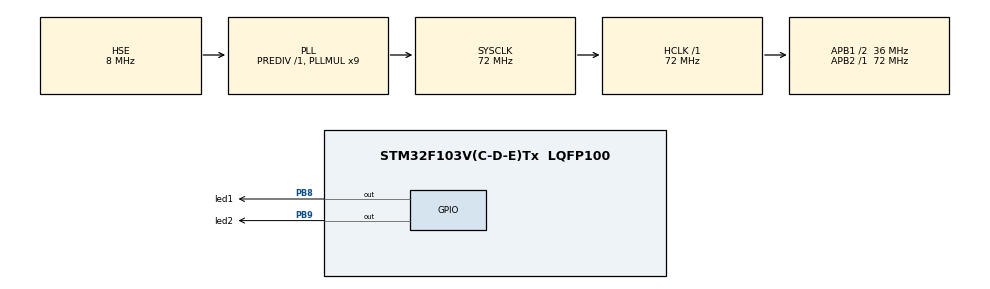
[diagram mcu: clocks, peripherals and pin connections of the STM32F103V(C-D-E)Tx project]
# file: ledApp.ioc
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Mcu.Family=STM32F1
RCC.PLLSourceVirtual=RCC_PLLSOURCE_HSE
PC15-OSC32_OUT.Mode=LSE-External-Oscillator
PB9.GPIO_Label=led2
RCC.APB1CLKDivider=RCC_HCLK_DIV2
PC14-OSC32_IN.Signal=RCC_OSC32_IN
RCC.SYSCLKSource=RCC_SYSCLKSOURCE_PLLCLK
ProjectManager.StackSize=0x400
PA13.Signal=SYS_JTMS-SWDIO
PB8.GPIO_Label=led1
ProjectManager.TargetToolchain=MDK-ARM V5
RCC.HCLKFreq_Value=72000000
RCC.APB2TimFreq_Value=72000000
OSC_IN.Signal=RCC_OSC_IN
RCC.USBFreq_Value=72000000
OSC_OUT.Mode=HSE-External-Oscillator
OSC_OUT.Signal=RCC_OSC_OUT
PC15-OSC32_OUT.Signal=RCC_OSC32_OUT
RCC.AHBFreq_Value=72000000
PB3.Mode=JTAG_5_pins
board=custom
PA15.Mode=JTAG_5_pins
RCC.PLLMUL=RCC_PLL_MUL9
RCC.APB2Freq_Value=72000000
PB4.Mode=JTAG_5_pins
PC14-OSC32_IN.Mode=LSE-External-Oscillator
PA14.Mode=JTAG_5_pins
PA13.Mode=JTAG_5_pins
Mcu.Name=STM32F103V(C-D-E)Tx
PB3.Signal=SYS_JTDO-TRACESWO
RCC.SYSCLKFreq_VALUE=72000000
Mcu.Package=LQFP100
PB9.Signal=GPIO_Output
OSC_IN.Mode=HSE-External-Oscillator
PA14.Signal=SYS_JTCK-SWCLK
PA15.Signal=SYS_JTDI
ProjectManager.HeapSize=0x200
NVIC.PriorityGroup=NVIC_PRIORITYGROUP_4
RCC.APB1TimFreq_Value=72000000
PB8.Signal=GPIO_Output
RCC.APB1Freq_Value=36000000
PB4.Signal=SYS_NJTRST

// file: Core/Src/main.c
/* USER CODE BEGIN Header */
/**
  ******************************************************************************
  * @file           : main.c
  * @brief          : Main program body
  ******************************************************************************
  * @attention
  *
  * <h2><center>&copy; Copyright (c) 2021 STMicroelectronics.
  * All rights reserved.</center></h2>
  *
  * This software component is licensed by ST under BSD 3-Clause license,
  * the "License"; You may not use this file except in compliance with the
  * License. You may obtain a copy of the License at:
  *                        opensource.org/licenses/BSD-3-Clause
  *
  ******************************************************************************
  */
/* USER CODE END Header */
#include "main.h"
#include "gpio.h"

void SystemClock_Config(void);
/* USER CODE BEGIN PFP */
void Delay(int t)
{
	for(int i=0;i<t;++i)
	{
		for(int j=0;j<12000;++j);
	}
}
/* USER CODE END PFP */

int main(void)
{
  /* USER CODE BEGIN 1 */
	//SystemInit();
	 SCB->VTOR = 0x08014000;
  /* USER CODE END 1 */

  /* MCU Configuration--------------------------------------------------------*/

  /* Reset of all peripherals, Initializes the Flash interface and the Systick. */
  HAL_Init();

  /* Configure the system clock */
  SystemClock_Config();

  /* Initialize all configured peripherals */
  MX_GPIO_Init();

  /* Infinite loop */
  /* USER CODE BEGIN WHILE */
	uint8_t temp=0;
  while (1)
  {
		if(temp)
		{
			HAL_GPIO_WritePin(led1_GPIO_Port, led1_Pin, GPIO_PIN_SET);
			HAL_GPIO_WritePin(led2_GPIO_Port, led2_Pin, GPIO_PIN_SET);
			//HAL_Delay(500);
			Delay(500);
			temp=0;
		}
		else
		{
			HAL_GPIO_WritePin(led1_GPIO_Port, led1_Pin, GPIO_PIN_RESET);
			HAL_GPIO_WritePin(led2_GPIO_Port, led2_Pin, GPIO_PIN_RESET);
			//HAL_Delay(500);
			Delay(500);
			temp=1;
		}

    /* USER CODE END WHILE */

  }
}

void SystemClock_Config(void)
{
  RCC_OscInitTypeDef RCC_OscInitStruct = {0};
  RCC_ClkInitTypeDef RCC_ClkInitStruct = {0};

  /** Initializes the RCC Oscillators according to the specified parameters
  * in the RCC_OscInitTypeDef structure.
  */
  RCC_OscInitStruct.OscillatorType = RCC_OSCILLATORTYPE_HSE;
  RCC_OscInitStruct.HSEState = RCC_HSE_ON;
  RCC_OscInitStruct.HSEPredivValue = RCC_HSE_PREDIV_DIV1;
  RCC_OscInitStruct.HSIState = RCC_HSI_ON;
  RCC_OscInitStruct.PLL.PLLState = RCC_PLL_ON;
  RCC_OscInitStruct.PLL.PLLSource = RCC_PLLSOURCE_HSE;
  RCC_OscInitStruct.PLL.PLLMUL = RCC_PLL_MUL9;
  if (HAL_RCC_OscConfig(&RCC_OscInitStruct) != HAL_OK)
  {
    Error_Handler();
  }
  /** Initializes the CPU, AHB and APB buses clocks
  */
  RCC_ClkInitStruct.ClockType = RCC_CLOCKTYPE_HCLK|RCC_CLOCKTYPE_SYSCLK
                              |RCC_CLOCKTYPE_PCLK1|RCC_CLOCKTYPE_PCLK2;
  RCC_ClkInitStruct.SYSCLKSource = RCC_SYSCLKSOURCE_PLLCLK;
  RCC_ClkInitStruct.AHBCLKDivider = RCC_SYSCLK_DIV1;
  RCC_ClkInitStruct.APB1CLKDivider = RCC_HCLK_DIV2;
  RCC_ClkInitStruct.APB2CLKDivider = RCC_HCLK_DIV1;

  if (HAL_RCC_ClockConfig(&RCC_ClkInitStruct, FLASH_LATENCY_2) != HAL_OK)
  {
    Error_Handler();
  }
}

void Error_Handler(void)
{
  __disable_irq();
  while (1)
  {
  }
}

/************************ (C) COPYRIGHT STMicroelectronics *****END OF FILE****/
